AUTOSAR XML (schema 4-3-0)
# \copyright BMW AG 2016 - 2017
package /BMW/Platform/IntegrationSample/SwComponentTypes
  swc implementation IMPL_IntegrationSample: programming-language=C, sw-version=5.0.3, vendor-id=5, behavior=IB_IntegrationSample
    code-descriptors:
      code Code1: artifact-descriptors=autosar-engineering-object={short-label=-, category=-}
    resource consumption ResConsumption1
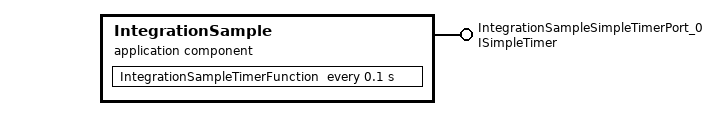
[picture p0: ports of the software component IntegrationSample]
  application sw component type IntegrationSample
    provide port IntegrationSampleSimpleTimerPort_0: mode-switch-sender-com-spec{mode-group=SimpleTimerMode, queue-length=2}, provided-interface=ISimpleTimer
    behavior IB_IntegrationSample: data-type-mapping=IntegrationSampleModemappingSimpleTimerMode, handle-termination-and-restart=NO-SUPPORT
      exclusive area EXA_IntegrationSample
      timing event IntegrationSample_SimpleTimer_TimingEvent: start-on-event=IntegrationSampleTimerFunction, period=0.1
      runnable IntegrationSampleTimerFunction: symbol=R_IntegrationSample_TimerFunction
        mode switch point MSP_SampleTimer_Mode_0: mode-group=IntegrationSampleSimpleTimerPort_0.SimpleTimerMode
